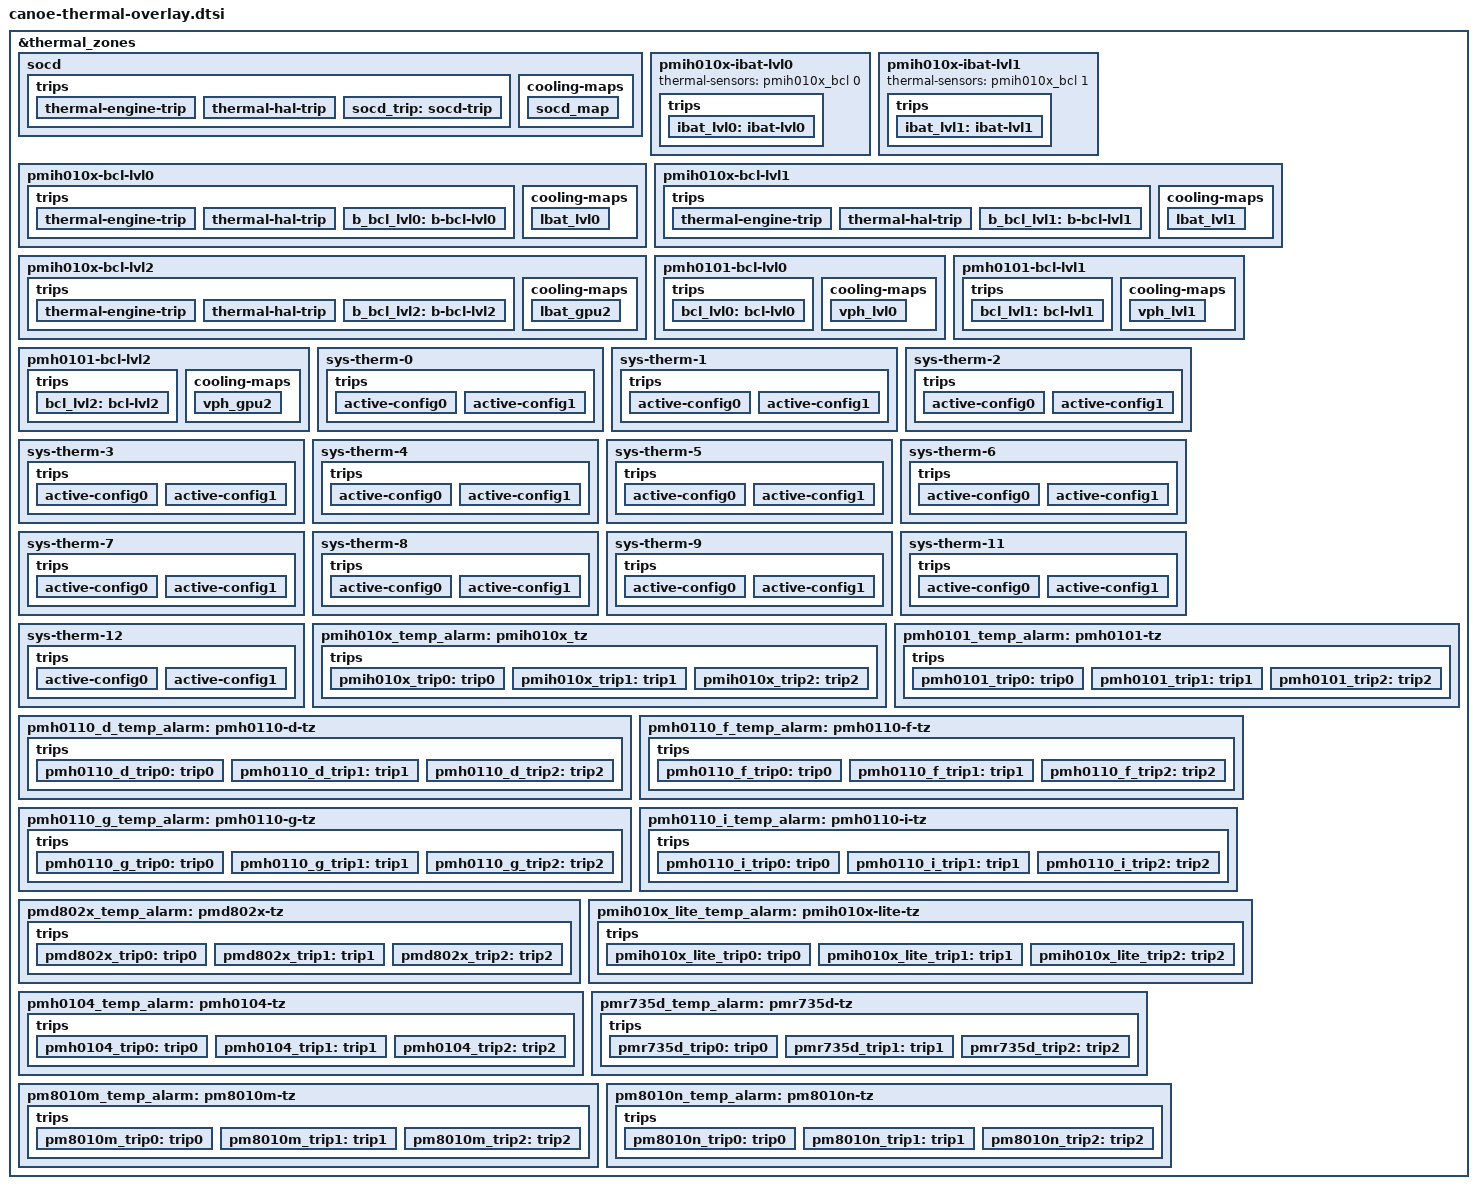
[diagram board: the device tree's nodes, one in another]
// SPDX-License-Identifier: BSD-3-Clause
/*
 * Copyright (c) 2024 Qualcomm Innovation Center, Inc. All rights reserved.
 */

&thermal_zones {
	socd {
		polling-delay-passive = <100>;
		thermal-sensors = <&bcl_soc>;

		trips {
			thermal-engine-trip {
				temperature = <100>;
				hysteresis = <0>;
				type = "passive";
			};

			thermal-hal-trip {
				temperature = <100>;
				hysteresis = <0>;
				type = "passive";
			};

			socd_trip: socd-trip {
				temperature = <90>;
				hysteresis = <0>;
				type = "passive";
			};
		};

		cooling-maps {
			socd_map {
				trip = <&socd_trip>;
				cooling-device = <&APC1_MX_CX_PAUSE 1 1
					&cdsp_sw 4 4
					&msm_gpu 4 4>;
			};
		};
	};

	pmih010x-ibat-lvl0 {
		thermal-sensors = <&pmih010x_bcl 0>;

		trips {
			ibat_lvl0:ibat-lvl0 {
				temperature = <13500>;
				hysteresis = <200>;
				type = "passive";
			};
		};
	};

	pmih010x-ibat-lvl1 {
		thermal-sensors = <&pmih010x_bcl 1>;

		trips {
			ibat_lvl1:ibat-lvl1 {
				temperature = <15000>;
				hysteresis = <200>;
				type = "passive";
			};
		};
	};

	pmih010x-bcl-lvl0 {
		polling-delay-passive = <100>;
		thermal-sensors = <&pmih010x_bcl 5>;

		trips {
			thermal-engine-trip {
				temperature = <100>;
				hysteresis = <0>;
				type = "passive";
			};

			thermal-hal-trip {
				temperature = <100>;
				hysteresis = <0>;
				type = "passive";
			};

			b_bcl_lvl0: b-bcl-lvl0 {
				temperature = <1>;
				hysteresis = <1>;
				type = "passive";
			};
		};

		cooling-maps {
			lbat_lvl0 {
				trip = <&b_bcl_lvl0>;
				cooling-device = <&modem_bcl 1 1
					&msm_gpu 1 1>;
			};
		};
	};

	pmih010x-bcl-lvl1 {
		polling-delay-passive = <100>;
		thermal-sensors = <&pmih010x_bcl 6>;

		trips {
			thermal-engine-trip {
				temperature = <100>;
				hysteresis = <0>;
				type = "passive";
			};

			thermal-hal-trip {
				temperature = <100>;
				hysteresis = <0>;
				type = "passive";
			};

			b_bcl_lvl1: b-bcl-lvl1 {
				temperature = <1>;
				hysteresis = <1>;
				type = "passive";
			};
		};

		cooling-maps {
			lbat_lvl1 {
				trip = <&b_bcl_lvl1>;
				cooling-device = <&modem_bcl 2 2
					&msm_gpu 2 2>;
			};
		};
	};

	pmih010x-bcl-lvl2 {
		polling-delay-passive = <100>;
		thermal-sensors = <&pmih010x_bcl 7>;

		trips {
			thermal-engine-trip {
				temperature = <100>;
				hysteresis = <0>;
				type = "passive";
			};

			thermal-hal-trip {
				temperature = <100>;
				hysteresis = <0>;
				type = "passive";
			};

			b_bcl_lvl2: b-bcl-lvl2 {
				temperature = <1>;
				hysteresis = <1>;
				type = "passive";
			};
		};

		cooling-maps {
			lbat_gpu2 {
				trip = <&b_bcl_lvl2>;
				cooling-device = <&msm_gpu 3 3>;
			};
		};
	};

	pmh0101-bcl-lvl0 {
		polling-delay-passive = <100>;
		thermal-sensors = <&pmh0101_bcl 5>;

		trips {
			bcl_lvl0: bcl-lvl0 {
				temperature = <1>;
				hysteresis = <1>;
				type = "passive";
			};
		};

		cooling-maps {
			vph_lvl0 {
				trip = <&bcl_lvl0>;
				cooling-device = <&modem_bcl 1 1
					&msm_gpu 1 1>;
			};
		};
	};

	pmh0101-bcl-lvl1 {
		polling-delay-passive = <100>;
		thermal-sensors = <&pmh0101_bcl 6>;

		trips {
			bcl_lvl1: bcl-lvl1 {
				temperature = <1>;
				hysteresis = <1>;
				type = "passive";
			};
		};

		cooling-maps {
			vph_lvl1 {
				trip = <&bcl_lvl1>;
				cooling-device = <&modem_bcl 2 2
					&msm_gpu 2 2>;
			};
		};
	};

	pmh0101-bcl-lvl2 {
		polling-delay-passive = <100>;
		thermal-sensors = <&pmh0101_bcl 7>;

		trips {
			bcl_lvl2: bcl-lvl2 {
				temperature = <1>;
				hysteresis = <1>;
				type = "passive";
			};
		};

		cooling-maps {
			vph_gpu2 {
				trip = <&bcl_lvl2>;
				cooling-device = <&msm_gpu 3 3>;
			};
		};
	};

	/* XO_THERM */
	sys-therm-0 {
		thermal-sensors = <&pmk8850_vadc
				   PMK8850_ADC5_GEN4_AMUX_THM1_XO_THERM_100K_PU(0, PMK8850_SID)>;

		trips {
			active-config0 {
				temperature = <125000>;
				hysteresis = <1000>;
				type = "passive";
			};

			active-config1 {
				temperature = <125000>;
				hysteresis = <1000>;
				type = "passive";
			};
		};
	};

	/* XOAGG_THERM */
	sys-therm-1 {
		thermal-sensors = <&pmk8850_vadc
				   PMK8850_ADC5_GEN4_AMUX2_GPIO7_100K_PU(0, PMK8850_SID)>;

		trips {
			active-config0 {
				temperature = <125000>;
				hysteresis = <1000>;
				type = "passive";
			};

			active-config1 {
				temperature = <125000>;
				hysteresis = <1000>;
				type = "passive";
			};
		};
	};

	/* SKIN_THERM */
	sys-therm-2 {
		thermal-sensors = <&pmk8850_vadc
				   PMH0101_ADC5_GEN4_AMUX_THM1_100K_PU(0, PMH0101_SID)>;

		trips {
			active-config0 {
				temperature = <125000>;
				hysteresis = <1000>;
				type = "passive";
			};

			active-config1 {
				temperature = <125000>;
				hysteresis = <1000>;
				type = "passive";
			};
		};
	};

	/* CAM_FLASH_THERM */
	sys-therm-3 {
		thermal-sensors = <&pmk8850_vadc
				   PMH0101_ADC5_GEN4_AMUX_THM2_100K_PU(0, PMH0101_SID)>;

		trips {
			active-config0 {
				temperature = <125000>;
				hysteresis = <1000>;
				type = "passive";
			};

			active-config1 {
				temperature = <125000>;
				hysteresis = <1000>;
				type = "passive";
			};
		};
	};

	/* WLAN_THERM */
	sys-therm-4 {
		thermal-sensors = <&pmk8850_vadc
				   PMH0101_ADC5_GEN4_AMUX_THM3_100K_PU(0, PMH0101_SID)>;

		trips {
			active-config0 {
				temperature = <125000>;
				hysteresis = <1000>;
				type = "passive";
			};

			active-config1 {
				temperature = <125000>;
				hysteresis = <1000>;
				type = "passive";
			};
		};
	};

	/* PA_THERM1 */
	sys-therm-5 {
		thermal-sensors = <&pmk8850_vadc
				   PMH0101_ADC5_GEN4_AMUX_THM4_100K_PU(0, PMH0101_SID)>;

		trips {
			active-config0 {
				temperature = <125000>;
				hysteresis = <1000>;
				type = "passive";
			};

			active-config1 {
				temperature = <125000>;
				hysteresis = <1000>;
				type = "passive";
			};
		};
	};

	/* QTM_THERM */
	sys-therm-6 {
		thermal-sensors = <&pmk8850_vadc
				   PMH0101_ADC5_GEN4_AMUX2_GPIO2_100K_PU(0, PMH0101_SID)>;

		trips {
			active-config0 {
				temperature = <125000>;
				hysteresis = <1000>;
				type = "passive";
			};

			active-config1 {
				temperature = <125000>;
				hysteresis = <1000>;
				type = "passive";
			};
		};
	};

	/* PA_THERM2 */
	sys-therm-7 {
		thermal-sensors = <&pmk8850_vadc
				   PMH0101_ADC5_GEN4_AMUX_THM6_GPIO3_100K_PU(0, PMH0101_SID)>;

		trips {
			active-config0 {
				temperature = <125000>;
				hysteresis = <1000>;
				type = "passive";
			};

			active-config1 {
				temperature = <125000>;
				hysteresis = <1000>;
				type = "passive";
			};
		};
	};

	/* WLS_THERM */
	sys-therm-8 {
		thermal-sensors = <&pmk8850_vadc
				   PMIH010X_ADC5_GEN4_AMUX4_GPIO12_100K_PU(1, PMIH010X_SID)>;

		trips {
			active-config0 {
				temperature = <125000>;
				hysteresis = <1000>;
				type = "passive";
			};

			active-config1 {
				temperature = <125000>;
				hysteresis = <1000>;
				type = "passive";
			};
		};
	};

	/* BATT_THERM */
	sys-therm-9 {
		thermal-sensors = <&pmk8850_vadc
				   PMIH010X_ADC5_GEN4_AMUX_THM1_BAT_THERM_100K_PU(1, PMIH010X_SID)>;

		trips {
			active-config0 {
				temperature = <125000>;
				hysteresis = <1000>;
				type = "passive";
			};

			active-config1 {
				temperature = <125000>;
				hysteresis = <1000>;
				type = "passive";
			};
		};
	};

	/* USB_THERM */
	sys-therm-11 {
		thermal-sensors = <&pmk8850_vadc
				   PMIH010X_ADC5_GEN4_AMUX_THM4_USB_THERM_100K_PU(1, PMIH010X_SID)>;

		trips {
			active-config0 {
				temperature = <125000>;
				hysteresis = <1000>;
				type = "passive";
			};

			active-config1 {
				temperature = <125000>;
				hysteresis = <1000>;
				type = "passive";
			};
		};
	};

	/* BATT2_THERM */
	sys-therm-12 {
		thermal-sensors = <&pmk8850_vadc
				   PMIH010X_ADC5_GEN4_AMUX3_BAT2_THERM_100K_PU(1, PMIH010X_SID)>;

		trips {
			active-config0 {
				temperature = <125000>;
				hysteresis = <1000>;
				type = "passive";
			};

			active-config1 {
				temperature = <125000>;
				hysteresis = <1000>;
				type = "passive";
			};
		};
	};

	pmih010x_temp_alarm: pmih010x_tz {
		polling-delay-passive = <100>;
		thermal-sensors = <&pmih010x_tz>;

		trips {
			pmih010x_trip0: trip0 {
				temperature = <95000>;
				hysteresis = <0>;
				type = "passive";
			};

			pmih010x_trip1: trip1 {
				temperature = <115000>;
				hysteresis = <0>;
				type = "hot";
			};

			pmih010x_trip2: trip2 {
				temperature = <145000>;
				hysteresis = <0>;
				type = "critical";
			};
		};
	};

	pmh0101_temp_alarm: pmh0101-tz {
		polling-delay-passive = <100>;
		thermal-sensors = <&pmh0101_tz>;

		trips {
			pmh0101_trip0: trip0 {
				temperature = <95000>;
				hysteresis = <0>;
				type = "passive";
			};

			pmh0101_trip1: trip1 {
				temperature = <115000>;
				hysteresis = <0>;
				type = "hot";
			};

			pmh0101_trip2: trip2 {
				temperature = <145000>;
				hysteresis = <0>;
				type = "critical";
			};
		};
	};

	pmh0110_d_temp_alarm: pmh0110-d-tz {
		polling-delay-passive = <100>;
		thermal-sensors = <&pmh0110_d_tz>;

		trips {
			pmh0110_d_trip0: trip0 {
				temperature = <95000>;
				hysteresis = <0>;
				type = "passive";
			};

			pmh0110_d_trip1: trip1 {
				temperature = <115000>;
				hysteresis = <0>;
				type = "hot";
			};

			pmh0110_d_trip2: trip2 {
				temperature = <145000>;
				hysteresis = <0>;
				type = "critical";
			};
		};
	};

	pmh0110_f_temp_alarm: pmh0110-f-tz {
		polling-delay-passive = <100>;
		thermal-sensors = <&pmh0110_f_tz>;

		trips {
			pmh0110_f_trip0: trip0 {
				temperature = <95000>;
				hysteresis = <0>;
				type = "passive";
			};

			pmh0110_f_trip1: trip1 {
				temperature = <115000>;
				hysteresis = <0>;
				type = "hot";
			};

			pmh0110_f_trip2: trip2 {
				temperature = <145000>;
				hysteresis = <0>;
				type = "critical";
			};
		};
	};

	pmh0110_g_temp_alarm: pmh0110-g-tz {
		polling-delay-passive = <100>;
		thermal-sensors = <&pmh0110_g_tz>;

		trips {
			pmh0110_g_trip0: trip0 {
				temperature = <95000>;
				hysteresis = <0>;
				type = "passive";
			};

			pmh0110_g_trip1: trip1 {
				temperature = <115000>;
				hysteresis = <0>;
				type = "hot";
			};

			pmh0110_g_trip2: trip2 {
				temperature = <145000>;
				hysteresis = <0>;
				type = "critical";
			};
		};
	};

	pmh0110_i_temp_alarm: pmh0110-i-tz {
		polling-delay-passive = <100>;
		thermal-sensors = <&pmh0110_i_tz>;

		trips {
			pmh0110_i_trip0: trip0 {
				temperature = <95000>;
				hysteresis = <0>;
				type = "passive";
			};

			pmh0110_i_trip1: trip1 {
				temperature = <115000>;
				hysteresis = <0>;
				type = "hot";
			};

			pmh0110_i_trip2: trip2 {
				temperature = <145000>;
				hysteresis = <0>;
				type = "critical";
			};
		};
	};

	pmd802x_temp_alarm: pmd802x-tz {
		polling-delay-passive = <100>;
		thermal-sensors = <&pmd802x_tz>;

		trips {
			pmd802x_trip0: trip0 {
				temperature = <95000>;
				hysteresis = <0>;
				type = "passive";
			};

			pmd802x_trip1: trip1 {
				temperature = <115000>;
				hysteresis = <0>;
				type = "hot";
			};

			pmd802x_trip2: trip2 {
				temperature = <145000>;
				hysteresis = <0>;
				type = "critical";
			};
		};
	};

	pmih010x_lite_temp_alarm: pmih010x-lite-tz {
		polling-delay-passive = <100>;
		thermal-sensors = <&pmih010x_lite_tz>;

		trips {
			pmih010x_lite_trip0: trip0 {
				temperature = <125000>;
				hysteresis = <0>;
				type = "passive";
			};

			pmih010x_lite_trip1: trip1 {
				temperature = <135000>;
				hysteresis = <0>;
				type = "hot";
			};

			pmih010x_lite_trip2: trip2 {
				temperature = <145000>;
				hysteresis = <0>;
				type = "critical";
			};
		};
	};

	pmh0104_temp_alarm: pmh0104-tz {
		polling-delay-passive = <100>;
		thermal-sensors = <&pmh0104_tz>;

		trips {
			pmh0104_trip0: trip0 {
				temperature = <95000>;
				hysteresis = <0>;
				type = "passive";
			};

			pmh0104_trip1: trip1 {
				temperature = <115000>;
				hysteresis = <0>;
				type = "hot";
			};

			pmh0104_trip2: trip2 {
				temperature = <145000>;
				hysteresis = <0>;
				type = "critical";
			};
		};
	};

	pmr735d_temp_alarm: pmr735d-tz {
		polling-delay-passive = <100>;
		thermal-sensors = <&pmr735d_tz>;

		trips {
			pmr735d_trip0: trip0 {
				temperature = <95000>;
				hysteresis = <0>;
				type = "passive";
			};

			pmr735d_trip1: trip1 {
				temperature = <115000>;
				hysteresis = <0>;
				type = "hot";
			};

			pmr735d_trip2: trip2 {
				temperature = <145000>;
				hysteresis = <0>;
				type = "critical";
			};
		};
	};

	pm8010m_temp_alarm: pm8010m-tz {
		polling-delay-passive = <100>;
		thermal-sensors = <&pm8010m_tz>;

		trips {
			pm8010m_trip0: trip0 {
				temperature = <95000>;
				hysteresis = <0>;
				type = "passive";
			};

			pm8010m_trip1: trip1 {
				temperature = <115000>;
				hysteresis = <0>;
				type = "hot";
			};

			pm8010m_trip2: trip2 {
				temperature = <145000>;
				hysteresis = <0>;
				type = "critical";
			};
		};
	};

	pm8010n_temp_alarm: pm8010n-tz {
		polling-delay-passive = <100>;
		thermal-sensors = <&pm8010n_tz>;

		trips {
			pm8010n_trip0: trip0 {
				temperature = <95000>;
				hysteresis = <0>;
				type = "passive";
			};

			pm8010n_trip1: trip1 {
				temperature = <115000>;
				hysteresis = <0>;
				type = "hot";
			};

			pm8010n_trip2: trip2 {
				temperature = <145000>;
				hysteresis = <0>;
				type = "critical";
			};
		};
	};
};
